AUTOSAR XML (schema 00048)
package /#{AR_PACKAGE}/#{COMPONENT}_SwComponentTypes
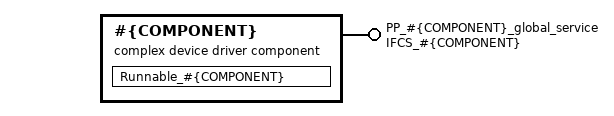
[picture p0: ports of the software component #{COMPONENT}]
  complex device driver sw component type #{COMPONENT}
    provide port PP_#{COMPONENT}_global_service: provided-interface=IFCS_#{COMPONENT}
    behavior IB_#{COMPONENT}: handle-termination-and-restart=CAN-BE-TERMINATED-AND-RESTARTED
      operation invoked event oie_PP_#{COMPONENT}_alive_#{COMPONENT}_global_service: start-on-event=Runnable_#{COMPONENT}, operation=PP_#{COMPONENT}_global_service.#{COMPONENT}_global_service
      runnable Runnable_#{COMPONENT}: arguments=[symbol=cmd_id, symbol=size_in_b, symbol=data], symbol=#{COMPONENT}_global_service
package /#{AR_PACKAGE}/#{COMPONENT}_SwcImplementations
  swc implementation Impl_#{COMPONENT}: programming-language=C, sw-version=1.0.0, vendor-id=#{VENDOR_ID}, behavior=IB_#{COMPONENT}
    code-descriptors:
      code SRC: artifact-descriptors=autosar-engineering-object={short-label=EngObject, category=SWSRC}
    resource consumption Resources
      memory section CODE: sw-addrmethod=CODE
